AUTOSAR XML (schema 00046)
package /ComponentTypes
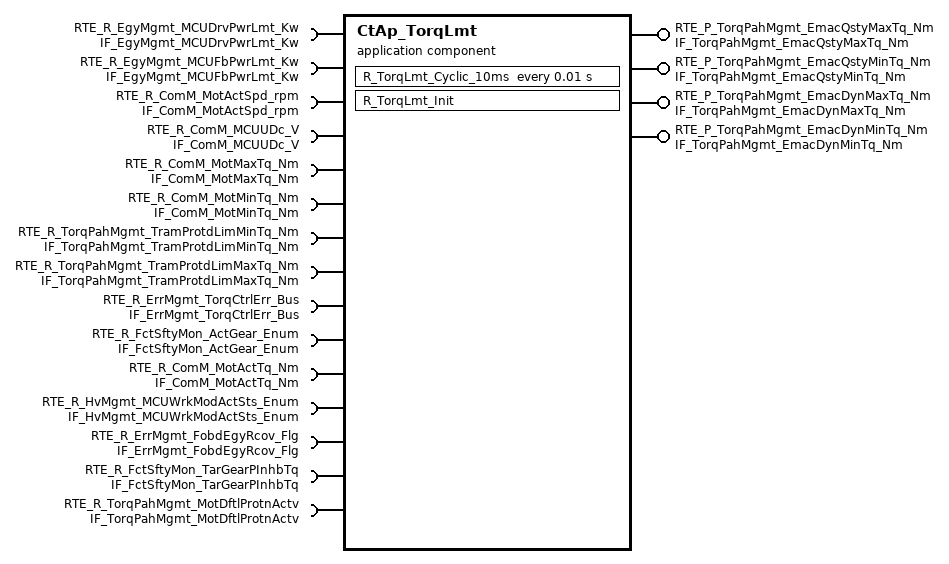
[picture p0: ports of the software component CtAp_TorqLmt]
  application sw component type CtAp_TorqLmt
    4 x provide port:
      RTE_P_TorqPahMgmt_EmacQstyMaxTq_Nm: nonqueued-sender-com-spec{data-element=tec_TorqPahMgmt_EmacQstyMaxTq_Nm, init-value=0}, provided-interface=IF_TorqPahMgmt_EmacQstyMaxTq_Nm
      RTE_P_TorqPahMgmt_EmacQstyMinTq_Nm: nonqueued-sender-com-spec{data-element=tec_TorqPahMgmt_EmacQstyMinTq_Nm, init-value=0}, provided-interface=IF_TorqPahMgmt_EmacQstyMinTq_Nm
      RTE_P_TorqPahMgmt_EmacDynMaxTq_Nm: nonqueued-sender-com-spec{data-element=tec_TorqPahMgmt_EmacDynMaxTq_Nm, init-value=0}, provided-interface=IF_TorqPahMgmt_EmacDynMaxTq_Nm
      RTE_P_TorqPahMgmt_EmacDynMinTq_Nm: nonqueued-sender-com-spec{data-element=tec_TorqPahMgmt_EmacDynMinTq_Nm, init-value=0}, provided-interface=IF_TorqPahMgmt_EmacDynMinTq_Nm
    15 x require port:
      RTE_R_EgyMgmt_MCUDrvPwrLmt_Kw: nonqueued-receiver-com-spec{data-element=tec_EgyMgmt_MCUDrvPwrLmt_Kw, filter=data-filter-type=ALWAYS, init-value=0}, required-interface=IF_EgyMgmt_MCUDrvPwrLmt_Kw
      RTE_R_EgyMgmt_MCUFbPwrLmt_Kw: nonqueued-receiver-com-spec{data-element=tec_EgyMgmt_MCUFbPwrLmt_Kw, filter=data-filter-type=ALWAYS, init-value=0}, required-interface=IF_EgyMgmt_MCUFbPwrLmt_Kw
      RTE_R_ComM_MotActSpd_rpm: nonqueued-receiver-com-spec{data-element=tec_ComM_MotActSpd_rpm, filter=data-filter-type=ALWAYS, init-value=0}, required-interface=IF_ComM_MotActSpd_rpm
      RTE_R_ComM_MCUUDc_V: nonqueued-receiver-com-spec{data-element=tec_ComM_MCUUDc_V, filter=data-filter-type=ALWAYS, init-value=0}, required-interface=IF_ComM_MCUUDc_V
      RTE_R_ComM_MotMaxTq_Nm: nonqueued-receiver-com-spec{data-element=tec_ComM_MotMaxTq_Nm, filter=data-filter-type=ALWAYS, init-value=0}, required-interface=IF_ComM_MotMaxTq_Nm
      RTE_R_ComM_MotMinTq_Nm: nonqueued-receiver-com-spec{data-element=tec_ComM_MotMinTq_Nm, filter=data-filter-type=ALWAYS, init-value=0}, required-interface=IF_ComM_MotMinTq_Nm
      RTE_R_TorqPahMgmt_TramProtdLimMinTq_Nm: nonqueued-receiver-com-spec{data-element=tec_TorqPahMgmt_TramProtdLmtMinTq_Nm, filter=data-filter-type=ALWAYS, init-value=0}, required-interface=IF_TorqPahMgmt_TramProtdLimMinTq_Nm
      RTE_R_TorqPahMgmt_TramProtdLimMaxTq_Nm: nonqueued-receiver-com-spec{data-element=tec_TorqPahMgmt_TramProtdLmtMaxTq_Nm, filter=data-filter-type=ALWAYS, init-value=0}, required-interface=IF_TorqPahMgmt_TramProtdLimMaxTq_Nm
      RTE_R_ErrMgmt_TorqCtrlErr_Bus: nonqueued-receiver-com-spec{data-element=tec_ErrMgmt_TorqCtrlErr_Bus, filter=data-filter-type=ALWAYS, init-value=fields=[ErrMgmt_DlyGrdtZeroTq_Flg:0, ErrMgmt_GrdtZeroTq_Flg:0, ErrMgmt_ImdtZeroTq_Flg:0, ErrMgmt_VehSpdLim_kph:0, ErrMgmt_VehSpdLimEna_Flg:0]}, required-interface=IF_ErrMgmt_TorqCtrlErr_Bus
      RTE_R_FctSftyMon_ActGear_Enum: nonqueued-receiver-com-spec{data-element=tec_FctSftyMon_ActGear_Enum, filter=data-filter-type=ALWAYS, init-value=0}, required-interface=IF_FctSftyMon_ActGear_Enum
      RTE_R_ComM_MotActTq_Nm: nonqueued-receiver-com-spec{data-element=tec_ComM_MotActTq_Nm, filter=data-filter-type=ALWAYS, init-value=0}, required-interface=IF_ComM_MotActTq_Nm
      RTE_R_HvMgmt_MCUWrkModActSts_Enum: nonqueued-receiver-com-spec{data-element=tec_HvMgmt_MCUWrkModActSts_Enum, filter=data-filter-type=ALWAYS, init-value=0}, required-interface=IF_HvMgmt_MCUWrkModActSts_Enum
      RTE_R_ErrMgmt_FobdEgyRcov_Flg: nonqueued-receiver-com-spec{data-element=tec_ErrMgmt_FobdEgyRcov_Flg, filter=data-filter-type=ALWAYS, init-value=0}, required-interface=IF_ErrMgmt_FobdEgyRcov_Flg
      RTE_R_FctSftyMon_TarGearPInhbTq: nonqueued-receiver-com-spec{data-element=tec_FctSftyMon_TarGearPInhbTq, filter=data-filter-type=ALWAYS, init-value=0}, required-interface=IF_FctSftyMon_TarGearPInhbTq
      RTE_R_TorqPahMgmt_MotDftlProtnActv: nonqueued-receiver-com-spec{data-element=tec_TorqPahMgmt_MotDftlProtnActv, filter=data-filter-type=ALWAYS, init-value=0}, required-interface=IF_TorqPahMgmt_MotDftlProtnActv
    behavior CtAp_TorqLmt_InternalBehavior
      timing event TMT_R_TorqLmt_Cyclic_10ms: start-on-event=R_TorqLmt_Cyclic_10ms, period=0.01
      init event CtAp_TorqLmt_InitEvent: start-on-event=R_TorqLmt_Init
      runnable R_TorqLmt_Cyclic_10ms
        data-receive-point-by-arguments:
          15 x access:
            REC_RTE_R_ComM_MCUUDc_V_tec_ComM_MCUUDc_V: accessed-variable=RTE_R_ComM_MCUUDc_V.tec_ComM_MCUUDc_V
            REC_RTE_R_ComM_MotActSpd_rpm_tec_ComM_MotActSpd_rpm: accessed-variable=RTE_R_ComM_MotActSpd_rpm.tec_ComM_MotActSpd_rpm
            REC_RTE_R_ComM_MotMaxTq_Nm_tec_ComM_MotMaxTq_Nm: accessed-variable=RTE_R_ComM_MotMaxTq_Nm.tec_ComM_MotMaxTq_Nm
            REC_RTE_R_ComM_MotMinTq_Nm_tec_ComM_MotMinTq_Nm: accessed-variable=RTE_R_ComM_MotMinTq_Nm.tec_ComM_MotMinTq_Nm
            REC_RTE_R_EgyMgmt_MCUDrvPwrLmt_Kw_tec_EgyMgmt_MCUDrvPwrLmt_Kw: accessed-variable=RTE_R_EgyMgmt_MCUDrvPwrLmt_Kw.tec_EgyMgmt_MCUDrvPwrLmt_Kw
            REC_RTE_R_EgyMgmt_MCUFbPwrLmt_Kw_tec_EgyMgmt_MCUFbPwrLmt_Kw: accessed-variable=RTE_R_EgyMgmt_MCUFbPwrLmt_Kw.tec_EgyMgmt_MCUFbPwrLmt_Kw
            REC_RTE_R_ErrMgmt_TorqCtrlErr_Bus_tec_ErrMgmt_TorqCtrlErr_Bus: accessed-variable=RTE_R_ErrMgmt_TorqCtrlErr_Bus.tec_ErrMgmt_TorqCtrlErr_Bus
            REC_RTE_R_TorqPahMgmt_TramProtdLimMaxTq_Nm_tec_TorqPahMgmt_TramProtdLmtMaxTq_Nm: accessed-variable=RTE_R_TorqPahMgmt_TramProtdLimMaxTq_Nm.tec_TorqPahMgmt_TramProtdLmtMaxTq_Nm
            REC_RTE_R_TorqPahMgmt_TramProtdLimMinTq_Nm_tec_TorqPahMgmt_TramProtdLmtMinTq_Nm: accessed-variable=RTE_R_TorqPahMgmt_TramProtdLimMinTq_Nm.tec_TorqPahMgmt_TramProtdLmtMinTq_Nm
            REC_RTE_R_ComM_MotActTq_Nm_tec_ComM_MotActTq_Nm: accessed-variable=RTE_R_ComM_MotActTq_Nm.tec_ComM_MotActTq_Nm
            REC_RTE_R_FctSftyMon_ActGear_Enum_tec_FctSftyMon_ActGear_Enum: accessed-variable=RTE_R_FctSftyMon_ActGear_Enum.tec_FctSftyMon_ActGear_Enum
            REC_RTE_R_HvMgmt_MCUWrkModActSts_Enum_tec_HvMgmt_MCUWrkModActSts_Enum: accessed-variable=RTE_R_HvMgmt_MCUWrkModActSts_Enum.tec_HvMgmt_MCUWrkModActSts_Enum
            REC_RTE_R_ErrMgmt_FobdEgyRcov_Flg_tec_ErrMgmt_FobdEgyRcov_Flg: accessed-variable=RTE_R_ErrMgmt_FobdEgyRcov_Flg.tec_ErrMgmt_FobdEgyRcov_Flg
            REC_RTE_R_FctSftyMon_TarGearPInhbTq_tec_FctSftyMon_TarGearPInhbTq: accessed-variable=RTE_R_FctSftyMon_TarGearPInhbTq.tec_FctSftyMon_TarGearPInhbTq
            REC_RTE_R_TorqPahMgmt_MotDftlProtnActv_tec_TorqPahMgmt_MotDftlProtnActv: accessed-variable=RTE_R_TorqPahMgmt_MotDftlProtnActv.tec_TorqPahMgmt_MotDftlProtnActv
        data-send-points:
          4 x access:
            SEND_RTE_P_TorqPahMgmt_EmacDynMaxTq_Nm_tec_TorqPahMgmt_EmacDynMaxTq_Nm: accessed-variable=RTE_P_TorqPahMgmt_EmacDynMaxTq_Nm.tec_TorqPahMgmt_EmacDynMaxTq_Nm
            SEND_RTE_P_TorqPahMgmt_EmacDynMinTq_Nm_tec_TorqPahMgmt_EmacDynMinTq_Nm: accessed-variable=RTE_P_TorqPahMgmt_EmacDynMinTq_Nm.tec_TorqPahMgmt_EmacDynMinTq_Nm
            SEND_RTE_P_TorqPahMgmt_EmacQstyMaxTq_Nm_tec_TorqPahMgmt_EmacQstyMaxTq_Nm: accessed-variable=RTE_P_TorqPahMgmt_EmacQstyMaxTq_Nm.tec_TorqPahMgmt_EmacQstyMaxTq_Nm
            SEND_RTE_P_TorqPahMgmt_EmacQstyMinTq_Nm_tec_TorqPahMgmt_EmacQstyMinTq_Nm: accessed-variable=RTE_P_TorqPahMgmt_EmacQstyMinTq_Nm.tec_TorqPahMgmt_EmacQstyMinTq_Nm
      runnable R_TorqLmt_Init
  swc implementation CtAp_TorqLmt_Implementation: behavior=CtAp_TorqLmt_InternalBehavior
